CM_ "IMPORT _vw_meb_common.dbc";

BO_ 190 MEB_HVEM_01: 48 XXX
 SG_ CRC : 0|8@1+ (1,0) [0|255] "" XXX
 SG_ CNT : 8|4@1+ (1,0) [0|15] "" XXX
 SG_ Engine_RPM_Max : 12|14@1+ (2,-9658) [0|15] "RPM" XXX
 SG_ Engine_RPM_Min : 26|14@1+ (2,-10300) [0|63] "RPM" XXX
 SG_ In_Motion_04 : 48|3@1+ (1,0) [0|7] "" XXX
 SG_ In_Motion_03 : 52|1@0+ (1,0) [0|1] "" XXX
 SG_ In_Motion_02 : 54|1@0+ (1,0) [0|1] "" XXX
 SG_ Engine_Power : 56|12@1+ (0.5,-1023) [0|255] "kW" XXX
 SG_ In_Motion : 68|1@1+ (1,0) [0|3] "" XXX
 SG_ Standstill : 71|1@0+ (1,0) [0|1] "" XXX
 SG_ Unknown_04 : 72|10@1+ (1,0) [0|255] "" XXX
 SG_ Battery_Voltage : 86|12@1+ (0.2,0) [0|3] "Volt" XXX
 SG_ Unknown_01 : 100|9@1+ (1,0) [0|7] "" XXX
 SG_ Battery_Voltage_02 : 113|11@1+ (0.24,0) [0|127] "Volt" XXX
 SG_ Engine_Status : 296|2@1+ (1,0) [0|3] "" XXX
 SG_ Inactive : 300|1@0+ (1,0) [0|1] "" XXX
 SG_ Inactive_02 : 303|1@0+ (1,0) [0|1] "" XXX

BO_ 252 ESC_51: 48 XXX
 SG_ CHECKSUM : 0|8@1+ (1,0) [0|255] "" XXX
 SG_ COUNTER : 8|4@1+ (1,0) [0|15] "" XXX
 SG_ AEB_Breaking_01 : 24|8@1+ (1,0) [0|255] "" XXX
 SG_ AEB_Breaking_02 : 32|8@1+ (1,0) [0|255] "" XXX
 SG_ Accelerator_Higher_Speed : 40|1@0+ (1,0) [0|1] "" XXX
 SG_ Brake_Pressure : 42|9@1+ (0.195,0) [0|100] "Unit_Percent" XXX
 SG_ HL_Radgeschw : 64|16@1+ (0.0075,0) [0|491.5125] "Unit_KilometerPerHour" XXX
 SG_ HR_Radgeschw : 80|16@1+ (0.0075,0) [0|491.5125] "Unit_KilometerPerHour" XXX
 SG_ VL_Radgeschw : 96|16@1+ (0.0075,0) [0|491.5125] "Unit_KilometerPerHour" XXX
 SG_ VR_Radgeschw : 112|16@1+ (0.0075,0) [0|491.5125] "Unit_KilometerPerHour" XXX
 SG_ HL_Brake_Pressure : 152|8@1+ (1,0) [0|100] "" XXX
 SG_ HR_Brake_Pressure : 160|8@1+ (1,0) [0|100] "" XXX
 SG_ VL_Brake_Pressure : 168|8@1+ (1,0) [0|100] "" XXX
 SG_ VR_Brake_Pressure : 176|8@1+ (1,0) [0|100] "" XXX
 SG_ Steering_Wheel_CW : 184|8@1+ (1.67,0) [0|255] "" XXX
 SG_ Steering_Wheel_CCW : 192|8@1+ (1.67,0) [0|255] "" XXX
 SG_ NEW_SIGNAL_2 : 14|6@1+ (1,0) [0|3] "" XXX
 SG_ NEW_SIGNAL_1 : 52|8@1+ (1,0) [0|15] "" XXX
 SG_ NEW_SIGNAL_3 : 128|4@1+ (1,0) [0|15] "" XXX
 SG_ ESC_v_Signal : 328|13@1+ (0.052,-107.016) [0|63] "" XXX
 SG_ NEW_SIGNAL_4 : 342|13@1+ (1,0) [0|3] "" XXX

BO_ 267 Motor_51: 32 XXX
 SG_ CHECKSUM : 0|8@1+ (1,0) [0|255] "" XXX
 SG_ COUNTER : 8|4@1+ (1,0) [0|15] "" XXX
 SG_ Accel_Pedal_Pressure : 12|9@1+ (0.4,0) [0|255] "" XXX
 SG_ Accel_Low_Pressed_Support : 21|1@1+ (1,0) [0|7] "" XXX
 SG_ TSK_Status : 88|3@1+ (1,0) [0|7] "" XXX
 SG_ TSK_Limiter_ausgewaehlt : 95|1@1+ (1,0) [0|3] "" XXX

BO_ 496 EA_02: 8 Gateway
 SG_ EA_02_CRC : 0|8@1+ (1,0) [0|255] "" Vector__XXX
 SG_ EA_02_BZ : 8|4@1+ (1,0) [0|15] "" Vector__XXX
 SG_ EA_Texte : 12|4@1+ (1,0) [0|15] "" ZR_High
 SG_ ACF_Lampe_Hands_Off : 16|2@1+ (1,0) [0|3] "" Vector__XXX
 SG_ EA_Infotainment_Anf : 22|2@1+ (1,0) [0|3] "" ZR_High,ZR_LIMU,ZR_MIB_TOP_ab_Gen3,ZR_Standard
 SG_ EA_Tueren_Anf : 24|1@1+ (1,0) [0|1] "" ZR_High
 SG_ EA_Innenraumlicht_Anf : 25|1@1+ (1,0) [0|1] "" ZR_High
 SG_ zFAS_Warnblinken : 26|2@1+ (1,0) [0|3] "" ZR_High
 SG_ STP_Primaeranz : 28|3@1+ (1,0) [0|7] "" Vector__XXX
 SG_ EA_Bremslichtblinken : 31|1@1+ (1,0) [0|1] "" Vector__XXX
 SG_ EA_Blinken : 32|3@1+ (1,0) [0|7] "" Vector__XXX
 SG_ EA_Unknown : 60|3@0+ (1,0) [0|7] "" XXX
 SG_ CHECKSUM : 0|8@1+ (1,0) [0|255] "" Vector__XXX
 SG_ COUNTER : 8|4@1+ (1,0) [0|15] "" Vector__XXX

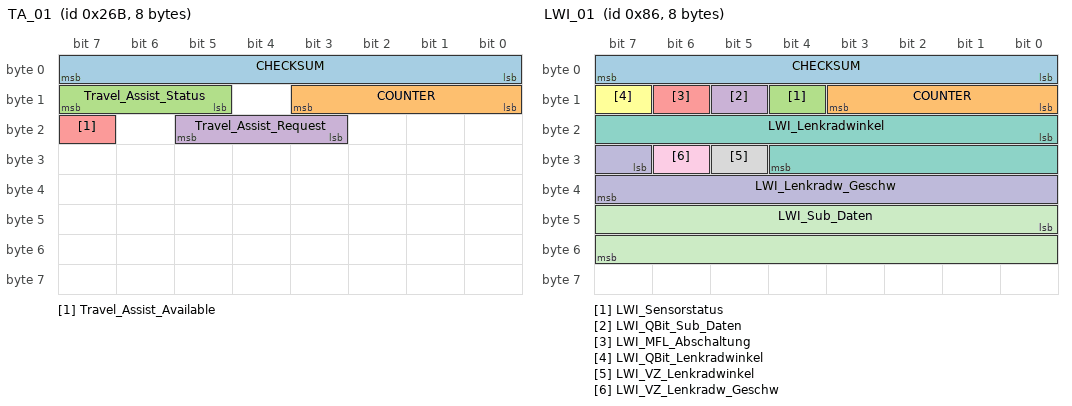
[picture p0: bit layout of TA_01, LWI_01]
BO_ 619 TA_01: 8 XXX
 SG_ CHECKSUM : 0|8@1+ (1,0) [0|255] "" XXX
 SG_ COUNTER : 8|4@1+ (1,0) [0|15] "" XXX
 SG_ Travel_Assist_Status : 13|3@1+ (1,0) [0|3] "" XXX
 SG_ Travel_Assist_Request : 19|3@1+ (1,0) [0|7] "" XXX
 SG_ Travel_Assist_Available : 23|1@1+ (1,0) [0|1] "" XXX

BO_ 768 ACC_19: 48 XXX
 SG_ ACC_Tempolimit : 64|5@1+ (1,0) [0|31] "" OTA_FC
 SG_ ACC_Wunschgeschw_Farbe : 69|1@1+ (1,0) [0|1] "" Vector__XXX
 SG_ ACC_Warnung_Verkehrszeichen_1 : 70|1@1+ (1,0) [0|1] "" Vector__XXX
 SG_ ACA_Querfuehrung : 71|2@1+ (1,0) [0|3] "" Vector__XXX
 SG_ Unknown_02 : 73|1@0+ (1,0) [0|1] "" XXX
 SG_ ACC_Regelung_AIO : 75|1@1+ (1,0) [0|1] "" ZR_High,ZR_LIMU,ZR_MIB_TOP_ab_Gen3
 SG_ ACC_Wunschgeschw_02 : 76|10@1+ (0.32,0) [0|327.04] "Unit_KiloMeterPerHour" Vector__XXX
 SG_ ACC_Abstandsindex_02 : 86|10@1+ (1,0) [1|1021] "" Vector__XXX
 SG_ ACC_Display_Prio : 96|2@1+ (1,0) [0|3] "" Vector__XXX
 SG_ ACC_rel_Objekt_Zusatzanz : 98|2@1+ (1,0) [0|3] "" Vector__XXX
 SG_ ACC_Gesetzte_Zeitluecke : 101|3@1+ (1,0) [0|7] "" Vector__XXX
 SG_ ACC_Optischer_Fahrerhinweis : 104|1@1+ (1,0) [0|1] "" Vector__XXX
 SG_ ACC_Warnhinweis : 105|1@1+ (1,0) [0|1] "" Vector__XXX
 SG_ ACC_EGO_Fahrzeug : 106|3@1+ (1,0) [0|7] "" Vector__XXX
 SG_ ACC_Relevantes_Objekt_02 : 109|2@1+ (1,0) [0|3] "" OTA_FC,ZR_High,ZR_LIMU,ZR_MIB_TOP_ab_Gen3
 SG_ ACC_Wunschgeschw_erreicht : 112|1@1+ (1,0) [0|1] "" OTA_FC
 SG_ ACC_Anzeige_Zeitluecke : 113|1@1+ (1,0) [0|1] "" Vector__XXX
 SG_ ACC_Texte_Primaeranz_02 : 114|6@1+ (1,0) [0|63] "" Vector__XXX
 SG_ ACC_Texte_Zusatzanz_02 : 120|6@1+ (1,0) [0|63] "" Vector__XXX
 SG_ STA_Primaeranz : 126|2@1+ (1,0) [0|3] "" Vector__XXX
 SG_ SET_ME_0X3FF : 140|10@1+ (1,0) [0|15] "" XXX
 SG_ Heartbeat : 150|9@1+ (1,0) [0|3] "" XXX
 SG_ SET_ME_0XFFFF : 160|16@1+ (1,0) [0|65535] "" XXX
 SG_ ACC_Enabled : 186|1@0+ (1,0) [0|1] "" XXX
 SG_ Zeitluecke_Farbe : 189|1@0+ (1,0) [0|1] "" XXX
 SG_ SET_ME_0X1 : 199|1@0+ (1,0) [0|1] "" XXX
 SG_ ACC_Status_ACC : 208|3@1+ (1,0) [0|7] "" XXX
 SG_ ACC_Akustischer_Fahrerhinweis : 211|2@1+ (1,0) [0|1] "" XXX
 SG_ Unknown_08 : 224|1@0+ (1,0) [0|1] "" XXX
 SG_ Unknown_01 : 225|1@0+ (1,0) [0|1] "" XXX
 SG_ Unknown_06 : 226|1@0+ (1,0) [0|1] "" XXX
 SG_ Unknown_07 : 228|1@0+ (1,0) [0|1] "" XXX
 SG_ SET_ME_0X7FFF : 240|16@1+ (1,0) [0|65535] "" XXX
 SG_ Unknown_09 : 262|1@0+ (1,0) [0|3] "" XXX
 SG_ Lead_Type_Detected : 265|1@0+ (1,0) [0|1] "" XXX
 SG_ ACC_Standby_Override : 266|1@0+ (1,0) [0|1] "" XXX
 SG_ Street_Color : 267|1@0+ (1,0) [0|1] "" XXX
 SG_ ACC_Limiter_Mode : 268|1@0+ (1,0) [0|1] "" XXX
 SG_ Lead_Brightness : 269|4@1+ (1,0) [0|7] "" XXX
 SG_ SET_ME_0X6A : 273|8@1+ (1,0) [0|7] "" XXX
 SG_ Lead_Type : 287|3@1+ (1,0) [0|3] "" XXX
 SG_ Lead_Distance : 290|10@1+ (0.2,0) [0|7] "Unit_Meter" XXX
 SG_ ACC_Events : 332|4@0+ (1,0) [0|3] "Unit_Meter" XXX
 SG_ Zeitluecke_1 : 334|9@1+ (0.171,0) [0|100] "Unit_Meter" XXX
 SG_ Zeitluecke_2 : 344|9@1+ (0.171,0) [0|100] "Unit_Meter" XXX
 SG_ Zeitluecke_3 : 354|9@1+ (0.171,0) [0|100] "Unit_Meter" XXX
 SG_ Zeitluecke_4 : 364|9@1+ (0.171,0) [0|100] "Unit_Meter" XXX
 SG_ Zeitluecke_5 : 374|9@1+ (0.171,0) [0|100] "Unit_Meter" XXX
 SG_ ACC_Event_Wunschgeschw : 140|10@1+ (0.32,0) [0|15] "" XXX
 SG_ Lead_Position : 281|2@1+ (1,0) [0|1] "" XXX
 SG_ Lead_Distance_Right : 300|10@1+ (0.2,0) [0|15] "Unit_Meter" XXX
 SG_ Lead_Distance_Left : 310|10@1+ (0.2,0) [0|3] "Unit_Meter" XXX

BO_ 134 LWI_01: 8 Gateway
 SG_ CHECKSUM : 0|8@1+ (1,0) [0|255] "" Vector__XXX
 SG_ COUNTER : 8|4@1+ (1,0) [0|15] "" Vector__XXX
 SG_ LWI_Sensorstatus : 12|1@1+ (1,0) [0|1] "" ZR_High,ZR_LIMU,ZR_MIB_TOP_ab_Gen3,ZR_Standard
 SG_ LWI_QBit_Sub_Daten : 13|1@1+ (1,0) [0|1] "" ZR_High
 SG_ LWI_MFL_Abschaltung : 14|1@1+ (1,0) [0|1] "" ZR_High
 SG_ LWI_QBit_Lenkradwinkel : 15|1@1+ (1,0) [0|1] "" ZR_High,ZR_LIMU,ZR_MIB_TOP_ab_Gen3,ZR_Standard
 SG_ LWI_Lenkradwinkel : 16|13@1+ (0.1,0) [0|800] "Unit_DegreOfArc" OTA_FC,ZR_High,ZR_LIMU,ZR_MIB_TOP_ab_Gen3,ZR_Standard
 SG_ LWI_VZ_Lenkradwinkel : 29|1@1+ (1,0) [0|1] "" OTA_FC,ZR_High,ZR_LIMU,ZR_MIB_TOP_ab_Gen3,ZR_Standard
 SG_ LWI_VZ_Lenkradw_Geschw : 30|1@1+ (1,0) [0|1] "" ZR_High
 SG_ LWI_Lenkradw_Geschw : 31|9@1+ (5,0) [0|2500] "Unit_DegreOfArcPerSecon" OTA_FC,ZR_High
 SG_ LWI_Sub_Daten : 40|16@1+ (1,0) [0|65535] "" Vector__XXX

BO_ 173 Getriebe_11: 8 Gateway
 SG_ CHECKSUM : 0|8@1+ (1,0) [0|255] "" Vector__XXX
 SG_ COUNTER : 8|4@1+ (1,0) [0|15] "" Vector__XXX
 SG_ GE_MMom_Soll_02 : 12|10@1+ (1,-509) [-509|509] "" Vector__XXX
 SG_ GE_MMom_Vorhalt_02 : 22|10@1+ (1,-509) [-509|509] "" Vector__XXX
 SG_ GE_Uefkt : 32|10@1+ (0.1,0) [0|102.2] "" Vector__XXX
 SG_ GE_Fahrstufe : 42|5@1+ (1,0) [0|31] "" DDA,OTA_FC,ZR_High,ZR_LIMU,ZR_MIB_TOP_ab_Gen3
 SG_ GE_reserv_Fahrstufe : 46|1@1+ (1,0) [0|1] "" Vector__XXX
 SG_ GE_Schaltablauf : 47|2@1+ (1,0) [0|3] "" Vector__XXX
 SG_ GE_Uefkt_unplausibel : 49|1@1+ (1,0) [0|1] "" Vector__XXX
 SG_ GE_MMom_Status_02 : 50|3@1+ (1,0) [0|7] "" Vector__XXX
 SG_ GE_Status_Kraftschluss : 53|3@1+ (1,0) [0|7] "" Vector__XXX
 SG_ GE_MMom_Status : 56|2@1+ (1,0) [0|3] "" Vector__XXX
 SG_ GE_Freig_MMom_Vorhalt : 58|1@1+ (1,0) [0|1] "" Vector__XXX
 SG_ GE_Verbot_Ausblendung : 59|1@1+ (1,0) [0|1] "" Vector__XXX
 SG_ GE_Zielgang : 60|4@1+ (1,0) [0|15] "" OTA_FC,ZR_High
 SG_ COUNTERXX : 8|4@1+ (1,0) [0|15] "" Gateway_MQB,Motor_Diesel_MQB,Motor_Hybrid_MQB,Motor_Otto_MQB
 SG_ GE_Schaltvorgang : 47|1@1+ (1,0) [0|1] "" Gateway_MQB,Motor_Diesel_MQB,Motor_Hybrid_MQB,Motor_Otto_MQB
 SG_ GE_Status_Kupplung : 54|2@1+ (1,0) [0|3] "" Gateway_MQB,Motor_Diesel_MQB,Motor_Hybrid_MQB,Motor_Otto_MQB

BO_ 299 GRA_ACC_01: 8 Gateway
 SG_ CHECKSUM : 0|8@1+ (1,0) [0|255] "" Vector__XXX
 SG_ COUNTER : 8|4@1+ (1,0) [0|15] "" Vector__XXX
 SG_ GRA_Hauptschalter : 12|1@1+ (1,0) [0|1] "" ZR_High
 SG_ GRA_Abbrechen : 13|1@1+ (1,0) [0|1] "" ZR_High
 SG_ GRA_Typ_Hauptschalter : 14|1@1+ (1,0) [0|1] "" ZR_High
 SG_ GRA_Limiter : 15|1@1+ (1,0) [0|1] "" ZR_High
 SG_ GRA_Tip_Setzen : 16|1@1+ (1,0) [0|1] "" ZR_High
 SG_ GRA_Tip_Hoch : 17|1@1+ (1,0) [0|1] "" ZR_High
 SG_ GRA_Tip_Runter : 18|1@1+ (1,0) [0|1] "" ZR_High
 SG_ GRA_Tip_Wiederaufnahme : 19|1@1+ (1,0) [0|1] "" ZR_High
 SG_ GRA_Verstellung_Zeitluecke : 20|2@1+ (1,0) [0|3] "" ZR_High
 SG_ GRA_Codierung : 22|2@1+ (1,0) [0|3] "" ZR_High
 SG_ GRA_Fehler : 24|1@1+ (1,0) [0|1] "" ZR_High
 SG_ GRA_LIM_Taste_verfuegbar : 25|1@1+ (1,0) [0|1] "" ZR_High
 SG_ GRA_Tip_Stufe_2 : 27|1@1+ (1,0) [0|1] "" ZR_High
 SG_ GRA_ButtonTypeInfo : 28|2@1+ (1,0) [0|1] "" ZR_High
 SG_ GRA_TravelAssist : 30|1@1+ (1,0) [0|1] "" Vector__XXX
 SG_ GRA_reserveByte4 : 31|1@1+ (1,0) [0|1] "" Vector__XXX
 SG_ GRA_reserveByte5 : 32|8@1+ (1,0) [0|255] "" Vector__XXX
 SG_ GRA_reserveByte6 : 40|8@1+ (1,0) [0|255] "" Vector__XXX
 SG_ GRA_reserveByte7 : 48|8@1+ (1,0) [0|255] "" Vector__XXX
 SG_ GRA_reserveByte8 : 56|8@1+ (1,0) [0|255] "" Vector__XXX
 SG_ GRA_Typ468 : 25|2@1+ (1,0) [0|3] "" Motor_Diesel_MQB,Motor_Hybrid_MQB,Motor_Otto_MQB
 SG_ MAYBE_TRAVEL_ASSIST : 30|1@1+ (1,0) [0|1] "" XXX

BO_ 332 Motor_54: 32 XXX
 SG_ CHECKSUM : 0|8@1+ (1,0) [0|255] "" XXX
 SG_ COUNTER : 8|4@1+ (1,0) [0|15] "" XXX
 SG_ Engine_On : 77|1@1+ (1,0) [0|1] "" XXX
 SG_ Accelerator_Pressure : 175|8@0+ (0.4,-14.4) [0|100] "Unit_Percent" XXX

BO_ 591 MEB_Distance_01: 64 XXX
 SG_ Unknown_01 : 12|1@0+ (1,0) [0|1] "" XXX
 SG_ Distance_Status : 13|2@1+ (1,0) [0|3] "" XXX
 SG_ Same_Lane_01_ObjectID : 16|6@1+ (1,0) [0|63] "Unit_ObjectID" XXX
 SG_ Left_Lane_01_ObjectID : 22|6@1+ (1,0) [0|63] "Unit_ObjectID" XXX
 SG_ Right_Lane_01_ObjectID : 28|6@1+ (1,0) [0|63] "Unit_ObjectID" XXX
 SG_ Same_Lane_02_ObjectID : 34|6@1+ (1,0) [0|63] "Unit_ObjectID" XXX
 SG_ Left_Lane_02_ObjectID : 40|6@1+ (1,0) [0|63] "Unit_ObjectID" XXX
 SG_ Right_Lane_02_ObjectID : 46|6@1+ (1,0) [0|63] "Unit_ObjectID" XXX
 SG_ Unknown_02 : 52|2@1+ (1,0) [0|3] "" XXX
 SG_ Unknown_03 : 54|10@1+ (1,0) [0|3] "" XXX
 SG_ Same_Lane_01_Long_Distance : 64|12@1+ (0.07,-6) [0|300] "Unit_Meter" XXX
 SG_ Same_Lane_01_Lat_Distance : 76|10@1+ (0.065,-33.28) [-50|50] "Unit_Meter" XXX
 SG_ Same_Lane_01_Rel_Velo : 86|10@1+ (0.28,-143.36) [-150|150] "Unit_MeterPerSecond" XXX
 SG_ Left_Lane_01_Long_Distance : 96|12@1+ (0.07,-6) [0|300] "Unit_Meter" XXX
 SG_ Left_Lane_01_Lat_Distance : 108|10@1+ (0.065,-33.28) [-50|50] "Unit_Meter" XXX
 SG_ Left_Lane_01_Rel_Velo : 118|10@1+ (0.28,-143.36) [-150|150] "Unit_MeterPerSecond" XXX
 SG_ Right_Lane_01_Long_Distance : 128|12@1+ (0.07,-6) [0|300] "Unit_Meter" XXX
 SG_ Right_Lane_01_Lat_Distance : 140|10@1+ (0.065,-33.28) [-50|50] "Unit_Meter" XXX
 SG_ Right_Lane_01_Rel_Velo : 150|10@1+ (0.28,-143.36) [-150|150] "Unit_MeterPerSecond" XXX
 SG_ Same_Lane_02_Long_Distance : 160|12@1+ (0.07,-6) [0|300] "Unit_Meter" XXX
 SG_ Same_Lane_02_Lat_Distance : 172|10@1+ (0.065,-33.28) [-50|50] "Unit_Meter" XXX
 SG_ Same_Lane_02_Rel_Velo : 182|10@1+ (0.28,-143.36) [-150|150] "Unit_MeterPerSecond" XXX
 SG_ Left_Lane_02_Long_Distance : 192|12@1+ (0.07,-6) [0|300] "Unit_Meter" XXX
 SG_ Left_Lane_02_Lat_Distance : 204|10@1+ (0.065,-33.28) [-50|50] "Unit_Meter" XXX
 SG_ Left_Lane_02_Rel_Velo : 214|10@1+ (0.28,-143.36) [-150|150] "Unit_MeterPerSecond" XXX
 SG_ Right_Lane_02_Long_Distance : 224|12@1+ (0.07,-6) [0|300] "Unit_Meter" XXX
 SG_ Right_Lane_02_Lat_Distance : 236|10@1+ (0.065,-33.28) [-50|50] "Unit_Meter" XXX
 SG_ Right_Lane_02_Rel_Velo : 246|10@1+ (0.28,-143.36) [-150|150] "Unit_MeterPerSecond" XXX
 SG_ Unknown_04 : 256|8@1+ (1,-128) [0|31] "" XXX
 SG_ Unknown_05 : 264|6@1+ (1,-15) [0|31] "" XXX
 SG_ Unknown_06 : 270|6@1+ (1,0) [0|127] "" XXX
 SG_ Unknown_07 : 277|6@1+ (1,0) [0|7] "" XXX
 SG_ Unknown_08 : 284|6@1+ (1,0) [0|1] "" XXX
 SG_ Same_Lane_01_Unknown_01 : 256|8@1+ (1,-128) [0|31] "" XXX
 SG_ Same_Lane_01_Unknown_02 : 264|6@1+ (1,-15) [0|31] "" XXX
 SG_ Same_Lane_01_Unknown_03 : 270|6@1+ (1,0) [0|127] "" XXX
 SG_ Same_Lane_01_Unknown_04 : 277|6@1+ (1,0) [0|7] "" XXX
 SG_ Same_Lane_01_Unknown_05 : 284|6@1+ (1,0) [0|1] "" XXX

BO_ 219 AWV_03: 48 XXX
 SG_ CHECKSUM : 0|8@1+ (1,0) [0|255] "" XXX
 SG_ COUNTER : 8|4@1+ (1,0) [0|15] "" XXX
 SG_ AEB_Object_Status : 12|3@1+ (1,0) [0|7] "" XXX
 SG_ VRU_Detected : 15|1@1+ (1,0) [0|1] "" XXX
 SG_ AWV_Unavailable : 17|1@1+ (1,0) [0|1] "" XXX
 SG_ Unknown_18 : 18|6@1+ (1,0) [0|63] "" XXX
 SG_ AEB_Object_Status_B : 24|3@1+ (1,0) [0|7] "" XXX
 SG_ Unknown_27 : 27|5@1+ (1,0) [0|31] "" XXX
 SG_ SET_ME_254 : 32|8@1+ (1,0) [0|255] "" XXX
 SG_ AEB_TTC_Countdown : 40|8@1+ (1,0) [0|255] "" XXX
 SG_ Active : 64|1@1+ (1,0) [0|1] "" XXX
 SG_ AEB_Active : 65|1@1+ (1,0) [0|1] "" XXX
 SG_ AEB_Target_Decel : 66|10@1+ (0.01,-10.23) [-10.23|0] "Unit_MeterPerSeconSquar" XXX
 SG_ FCW_Active : 76|1@0+ (1,0) [0|1] "" XXX
 SG_ Unknown_80 : 80|8@1+ (1,0) [0|255] "" XXX
 SG_ AEB_Active_2 : 91|1@1+ (1,0) [0|1] "" XXX
 SG_ Unknown_93 : 93|7@1+ (1,0) [0|127] "" XXX
 SG_ Unknown_100 : 100|4@1+ (1,0) [0|15] "" XXX
 SG_ AWV_Init_Status : 128|2@1+ (1,0) [0|3] "" XXX
 SG_ Unknown_192 : 192|1@1+ (1,0) [0|1] "" XXX
 SG_ Pre_FCW : 64|1@0+ (1,0) [0|1] "" XXX

VAL_ 768 ACC_Events 3 "Starting_Available" 0 "None" 5 "Speed_Limit_Camera" 9 "Street_Type" 4 "Speed_Limit_in_Nav";
